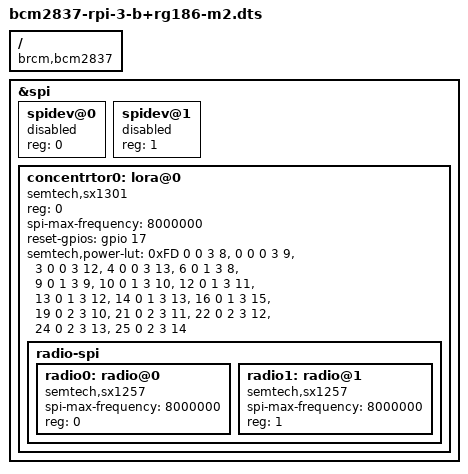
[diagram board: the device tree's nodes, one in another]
/*
 * Copyright (c) 2019 Ben Whitten
 *
 * SPDX-License-Identifier: GPL-2.0+ OR MIT
 */

/dts-v1/;
/plugin/;

/ {
	compatible = "brcm,bcm2837";

	#address-cells = <1>;
	#size-cells = <0>;

	fragment@0 {
		reg = <0>;

		target = <&spi>;

		__overlay__ {
			status = "okay";

			#address-cells = <1>;
			#size-cells = <0>;

			spidev@0 {
				reg = <0>;
				status = "disabled";
			};

			spidev@1 {
				reg = <1>;
				status = "disabled";
			};

			concentrtor0: lora@0 {
				compatible = "semtech,sx1301";
				reg = <0>;
				spi-max-frequency = <8000000>;
				reset-gpios = <&gpio 17 0>;

				semtech,power-lut =
					/bits/ 8 < 0xFD 0 0 3  8 >,
					/bits/ 8 <    0 0 0 3  9 >,
					/bits/ 8 <    3 0 0 3 12 >,
					/bits/ 8 <    4 0 0 3 13 >,
					/bits/ 8 <    6 0 1 3  8 >,
					/bits/ 8 <    9 0 1 3  9 >,
					/bits/ 8 <   10 0 1 3 10 >,
					/bits/ 8 <   12 0 1 3 11 >,
					/bits/ 8 <   13 0 1 3 12 >,
					/bits/ 8 <   14 0 1 3 13 >,
					/bits/ 8 <   16 0 1 3 15 >,
					/bits/ 8 <   19 0 2 3 10 >,
					/bits/ 8 <   21 0 2 3 11 >,
					/bits/ 8 <   22 0 2 3 12 >,
					/bits/ 8 <   24 0 2 3 13 >,
					/bits/ 8 <   25 0 2 3 14 >;

				radio-spi {
					#address-cells = <1>;
					#size-cells = <0>;

					radio0: radio@0 {
						compatible = "semtech,sx1257";
						spi-max-frequency = <8000000>;
						reg = <0>;
					};

					radio1: radio@1 {
						compatible = "semtech,sx1257";
						spi-max-frequency = <8000000>;
						reg = <1>;
					};
				};
			};
		};
	};
};
